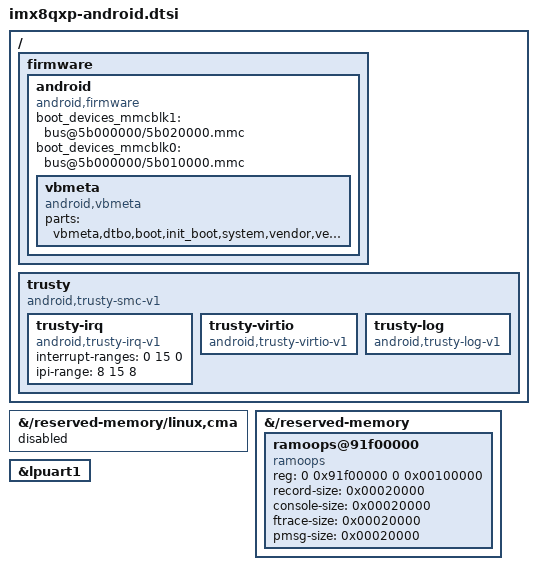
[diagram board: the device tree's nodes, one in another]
// SPDX-License-Identifier: (GPL-2.0+ OR MIT)
/*
 * Copyright 2022 NXP
 */

/ {
	firmware {
		android {
			compatible = "android,firmware";
			/* sd card node which used if androidboot.boot_device_root=mmcblk1 */
			boot_devices_mmcblk1 = "bus@5b000000/5b020000.mmc";
			/* emmc node which used if androidboot.boot_device_root=mmcblk0 */
			boot_devices_mmcblk0 = "bus@5b000000/5b010000.mmc";
			vbmeta {
				/*we need use FirstStageMountVBootV2 if we enable avb*/
				compatible = "android,vbmeta";
				/*parts means the partition witch can be mount in first stage*/
				parts = "vbmeta,dtbo,boot,init_boot,system,vendor,vendor_dlkm,product";
			};
		};
	};

	trusty {
		compatible = "android,trusty-smc-v1";
		ranges;
		#address-cells = <2>;
		#size-cells = <2>;
		trusty-irq {
			compatible = "android,trusty-irq-v1";
			interrupt-ranges = < 0 15 0>;
			ipi-range = <8 15 8>;
		};
		trusty-virtio {
			compatible = "android,trusty-virtio-v1";
		};
		trusty-log {
			compatible = "android,trusty-log-v1";
		};
	};
};

&{/reserved-memory/linux,cma} {
	status = "disabled";
};

&{/reserved-memory} {
	ramoops@91f00000 {
		compatible = "ramoops";
		reg = <0 0x91f00000 0 0x00100000>;
		record-size     = <0x00020000>;
		console-size    = <0x00020000>;
		ftrace-size     = <0x00020000>;
		pmsg-size       = <0x00020000>;
	};
};

&lpuart1 {
       /delete-node/ bluetooth;
};
